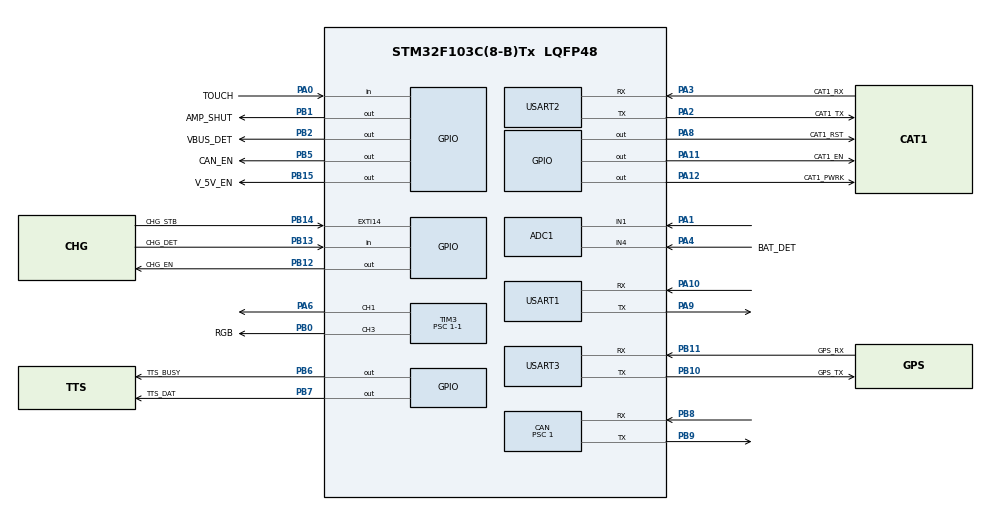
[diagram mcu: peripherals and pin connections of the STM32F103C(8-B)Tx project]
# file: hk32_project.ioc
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ADC1.Channel-0\#ChannelRegularConversion=ADC_CHANNEL_1
ADC1.NbrOfConversionFlag=1
ADC1.Rank-0\#ChannelRegularConversion=1
ADC1.SamplingTime-0\#ChannelRegularConversion=ADC_SAMPLETIME_1CYCLE_5
ADC1.master=1
CAN.BS1=CAN_BS1_4TQ
CAN.BS2=CAN_BS2_3TQ
CAN.CalculateBaudRate=1000000
CAN.CalculateTimeBit=1000
CAN.CalculateTimeQuantum=125.0
CAN.Prescaler=1
Dma.Request0=TIM3_CH3
Dma.TIM3_CH3.0.Direction=DMA_MEMORY_TO_PERIPH
Dma.TIM3_CH3.0.Instance=DMA1_Channel2
Dma.TIM3_CH3.0.MemDataAlignment=DMA_MDATAALIGN_BYTE
Dma.TIM3_CH3.0.MemInc=DMA_MINC_ENABLE
Dma.TIM3_CH3.0.Mode=DMA_NORMAL
Dma.TIM3_CH3.0.PeriphDataAlignment=DMA_PDATAALIGN_HALFWORD
Dma.TIM3_CH3.0.PeriphInc=DMA_PINC_DISABLE
Dma.TIM3_CH3.0.Priority=DMA_PRIORITY_LOW
Mcu.Family=STM32F1
Mcu.Name=STM32F103C(8-B)Tx
Mcu.Package=LQFP48
NVIC.CAN1_RX1_IRQn=true\:0\:0\:false\:false\:true\:true\:true\:true
NVIC.DMA1_Channel2_IRQn=true\:0\:0\:false\:false\:true\:false\:true\:true
NVIC.PriorityGroup=NVIC_PRIORITYGROUP_4
NVIC.RTC_Alarm_IRQn=true\:0\:0\:false\:false\:true\:true\:true\:true
NVIC.RTC_IRQn=true\:0\:0\:false\:false\:true\:true\:true\:true
NVIC.TIM4_IRQn=true\:4\:0\:true\:false\:true\:true\:true\:true
PA0-WKUP.GPIO_Label=TOUCH
PA0-WKUP.Signal=GPIO_Input
PA1.Signal=ADCx_IN1
PA10.Mode=Asynchronous
PA10.Signal=USART1_RX
PA11.GPIO_Label=CAT1_EN
PA11.Signal=GPIO_Output
PA12.GPIO_Label=CAT1_PWRK
PA12.Signal=GPIO_Output
PA13.Mode=Serial_Wire
PA13.Signal=SYS_JTMS-SWDIO
PA14.Mode=Serial_Wire
PA14.Signal=SYS_JTCK-SWCLK
PA2.GPIO_Label=CAT1_TX
PA2.Mode=Asynchronous
PA2.Signal=USART2_TX
PA3.GPIO_Label=CAT1_RX
PA3.Mode=Asynchronous
PA3.Signal=USART2_RX
PA4.GPIO_Label=BAT_DET
PA4.Signal=ADCx_IN4
PA6.Signal=S_TIM3_CH1
PA8.GPIO_Label=CAT1_RST
PA8.Signal=GPIO_Output
PA9.Mode=Asynchronous
PA9.Signal=USART1_TX
PB0.GPIO_Label=RGB
PB0.Signal=S_TIM3_CH3
PB1.GPIO_Label=AMP_SHUT
PB1.Signal=GPIO_Output
PB10.GPIO_Label=GPS_TX
PB10.Mode=Asynchronous
PB10.Signal=USART3_TX
PB11.GPIO_Label=GPS_RX
PB11.Mode=Asynchronous
PB11.Signal=USART3_RX
PB12.GPIO_Label=CHG_EN
PB12.Signal=GPIO_Output
PB13.GPIO_Label=CHG_DET
PB13.Signal=GPIO_Input
PB14.GPIO_Label=CHG_STB
PB14.Signal=GPXTI14
PB15.GPIO_Label=V_5V_EN
PB15.Signal=GPIO_Output
PB2.GPIO_Label=VBUS_DET
PB2.Signal=GPIO_Output
PB5.GPIO_Label=CAN_EN
PB5.Signal=GPIO_Output
PB6.GPIO_Label=TTS_BUSY
PB6.Signal=GPIO_Output
PB7.GPIO_Label=TTS_DAT
PB7.Signal=GPIO_Output
PB8.Mode=CAN_Activate
PB8.Signal=CAN_RX
PB9.Mode=CAN_Activate
PB9.Signal=CAN_TX
PC14-OSC32_IN.Mode=LSE-External-Oscillator
PC14-OSC32_IN.Signal=RCC_OSC32_IN
PC15-OSC32_OUT.Mode=LSE-External-Oscillator
PC15-OSC32_OUT.Signal=RCC_OSC32_OUT
PD0-OSC_IN.Mode=HSE-External-Oscillator
PD0-OSC_IN.Signal=RCC_OSC_IN
PD1-OSC_OUT.Mode=HSE-External-Oscillator
PD1-OSC_OUT.Signal=RCC_OSC_OUT
ProjectManager.HeapSize=0x200
ProjectManager.StackSize=0x400
ProjectManager.TargetToolchain=MDK-ARM V5.32
RCC.APB1Freq_Value=8000000
RCC.APB2Freq_Value=8000000
RTC.Date=2
RTC.Year=24
SH.ADCx_IN1.0=ADC1_IN1,IN1
SH.ADCx_IN4.0=ADC1_IN4,IN4
SH.S_TIM3_CH1.0=TIM3_CH1,PWM Generation1 CH1
SH.S_TIM3_CH3.0=TIM3_CH3,PWM Generation3 CH3
TIM3.Channel-PWM\ Generation1\ CH1=TIM_CHANNEL_1
TIM3.Channel-PWM\ Generation3\ CH3=TIM_CHANNEL_3
TIM3.Period=50-1
TIM3.Prescaler=1-1
TIM4.Period=10000-1
TIM4.Prescaler=80-1
USART1.VirtualMode=VM_ASYNC
USART2.VirtualMode=VM_ASYNC
USART3.VirtualMode=VM_ASYNC
VP_RTC_VS_RTC_Activate.Mode=RTC_Enabled
VP_RTC_VS_RTC_Calendar.Mode=RTC_Calendar
VP_TIM4_VS_ClockSourceINT.Mode=Internal
board=custom

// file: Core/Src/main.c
/* USER CODE BEGIN Header */
/**
  ******************************************************************************
  * @file           : main.c
  * @brief          : Main program body
  ******************************************************************************
  * @attention
  *
  * Copyright (c) 2025 STMicroelectronics.
  * All rights reserved.
  *
  * This software is licensed under terms that can be found in the LICENSE file
  * in the root directory of this software component.
  * If no LICENSE file comes with this software, it is provided AS-IS.
  *
  ******************************************************************************
  */
/* USER CODE END Header */
#include "main.h"
#include "adc.h"
#include "can.h"
#include "dma.h"
#include "rtc.h"
#include "tim.h"
#include "usart.h"
#include "gpio.h"

/* USER CODE BEGIN Includes */
#include "main_task.hpp"
/* USER CODE END Includes */

void SystemClock_Config(void);

int main(void)
{

  /* MCU Configuration--------------------------------------------------------*/

  /* Reset of all peripherals, Initializes the Flash interface and the Systick. */
  HAL_Init();

  /* Configure the system clock */
  SystemClock_Config();

  /* Initialize all configured peripherals */
  MX_GPIO_Init();
  MX_DMA_Init();
  MX_ADC1_Init();
  MX_USART2_UART_Init();
  MX_CAN_Init();
  MX_TIM3_Init();
  MX_USART1_UART_Init();
  MX_USART3_UART_Init();
  MX_TIM4_Init();
  MX_RTC_Init();
  /* USER CODE BEGIN 2 */
    main_setup();
    main_task();
  /* USER CODE END 2 */

  /* Infinite loop */
  while (1)
  {

  }
}

void SystemClock_Config(void)
{
  RCC_OscInitTypeDef RCC_OscInitStruct = {0};
  RCC_ClkInitTypeDef RCC_ClkInitStruct = {0};
  RCC_PeriphCLKInitTypeDef PeriphClkInit = {0};

  /** Initializes the RCC Oscillators according to the specified parameters
  * in the RCC_OscInitTypeDef structure.
  */
  RCC_OscInitStruct.OscillatorType = RCC_OSCILLATORTYPE_HSI|RCC_OSCILLATORTYPE_LSI;
  RCC_OscInitStruct.HSIState = RCC_HSI_ON;
  RCC_OscInitStruct.HSICalibrationValue = RCC_HSICALIBRATION_DEFAULT;
  RCC_OscInitStruct.LSIState = RCC_LSI_ON;
  RCC_OscInitStruct.PLL.PLLState = RCC_PLL_NONE;
  if (HAL_RCC_OscConfig(&RCC_OscInitStruct) != HAL_OK)
  {
    Error_Handler();
  }

  /** Initializes the CPU, AHB and APB buses clocks
  */
  RCC_ClkInitStruct.ClockType = RCC_CLOCKTYPE_HCLK|RCC_CLOCKTYPE_SYSCLK
                              |RCC_CLOCKTYPE_PCLK1|RCC_CLOCKTYPE_PCLK2;
  RCC_ClkInitStruct.SYSCLKSource = RCC_SYSCLKSOURCE_HSI;
  RCC_ClkInitStruct.AHBCLKDivider = RCC_SYSCLK_DIV1;
  RCC_ClkInitStruct.APB1CLKDivider = RCC_HCLK_DIV1;
  RCC_ClkInitStruct.APB2CLKDivider = RCC_HCLK_DIV1;

  if (HAL_RCC_ClockConfig(&RCC_ClkInitStruct, FLASH_LATENCY_0) != HAL_OK)
  {
    Error_Handler();
  }
  PeriphClkInit.PeriphClockSelection = RCC_PERIPHCLK_RTC|RCC_PERIPHCLK_ADC;
  PeriphClkInit.RTCClockSelection = RCC_RTCCLKSOURCE_LSI;
  PeriphClkInit.AdcClockSelection = RCC_ADCPCLK2_DIV2;
  if (HAL_RCCEx_PeriphCLKConfig(&PeriphClkInit) != HAL_OK)
  {
    Error_Handler();
  }
}

void Error_Handler(void)
{
  __disable_irq();
  while (1)
  {
  }
}
